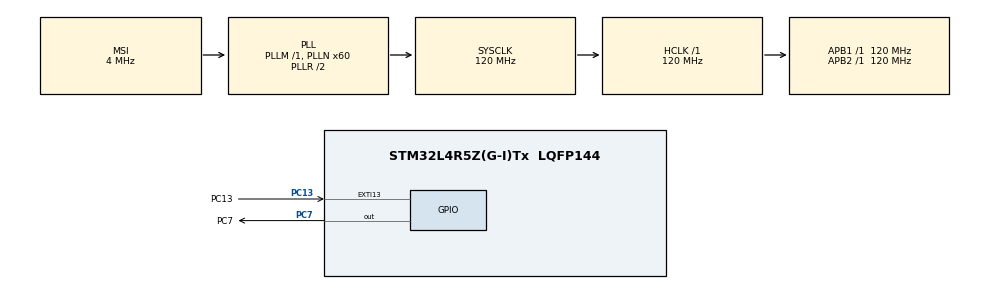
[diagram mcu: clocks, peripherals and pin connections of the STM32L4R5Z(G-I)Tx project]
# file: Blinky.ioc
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Mcu.Family=STM32L4
Mcu.Name=STM32L4R5Z(G-I)Tx
Mcu.Package=LQFP144
NVIC.EXTI15_10_IRQn=true\:1\:0\:true\:false\:true\:true\:true
NVIC.PriorityGroup=NVIC_PRIORITYGROUP_4
PA13\ (JTMS/SWDIO).Mode=Serial_Wire
PA13\ (JTMS/SWDIO).Signal=SYS_JTMS-SWDIO
PA14\ (JTCK/SWCLK).Mode=Serial_Wire
PA14\ (JTCK/SWCLK).Signal=SYS_JTCK-SWCLK
PC13.GPIO_Label=PC13
PC13.Signal=GPXTI13
PC7.GPIO_Label=PC7
PC7.GPIO_Speed=GPIO_SPEED_FREQ_HIGH
PC7.Signal=GPIO_Output
ProjectManager.HeapSize=0x200
ProjectManager.StackSize=0x400
ProjectManager.TargetToolchain=TrueSTUDIO
RCC.AHBFreq_Value=120000000
RCC.APB1Freq_Value=120000000
RCC.APB1TimFreq_Value=120000000
RCC.APB2Freq_Value=120000000
RCC.APB2TimFreq_Value=120000000
RCC.CortexFreq_Value=120000000
RCC.HCLKFreq_Value=120000000
RCC.HSE_VALUE=8000000
RCC.HSI48_VALUE=48000000
RCC.HSI_VALUE=16000000
RCC.LSE_VALUE=32768
RCC.MSI_VALUE=4000000
RCC.PLLN=60
RCC.SYSCLKFreq_VALUE=120000000
RCC.SYSCLKSource=RCC_SYSCLKSOURCE_PLLCLK
RCC.VCOOutputFreq_Value=240000000
board=custom

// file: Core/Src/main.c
/* USER CODE BEGIN Header */
/**
  ******************************************************************************
  * @file           : main.c
  * @brief          : Main program body
  ******************************************************************************
  * @attention
  *
  * Copyright (c) 2021 STMicroelectronics.
  * All rights reserved.
  *
  * This software is licensed under terms that can be found in the LICENSE file
  * in the root directory of this software component.
  * If no LICENSE file comes with this software, it is provided AS-IS.
  *
  ******************************************************************************
  */
/* USER CODE END Header */
#include "main.h"

void SystemClock_Config(void);
static void MX_GPIO_Init(void);

/* USER CODE BEGIN 0 */
uint8_t MODE_SELECTION;
/* USER CODE END 0 */

int main(void)
{

  /* MCU Configuration--------------------------------------------------------*/

  /* Reset of all peripherals, Initializes the Flash interface and the Systick. */
  HAL_Init();

  /* Configure the system clock */
  SystemClock_Config();

  /* Initialize all configured peripherals */
  MX_GPIO_Init();

  /* Infinite loop */
  while (1)
  {
// 	  if (MODE_SELECTION == 0) {

	  /* Toggle LEDs - Use the HAL functions from stm32l4xx_hal_gpio.c file */
	  HAL_GPIO_TogglePin(GPIOC, GPIO_PIN_7); //LD1 (green) – PC7
	  HAL_Delay(1000); //100ms // AMER: Updated this to 1000s to increase delay between each blink

//	Othman- function not needed, only blinking
// 	  } else if (MODE_SELECTION == 1) {
// 	  /* Turn OFF the LEDs - Use the HAL functions from stm32l4xx_hal_gpio.c file
// 	  */
// 	  HAL_GPIO_WritePin(GPIOC, GPIO_PIN_7, GPIO_PIN_RESET); //Turn off LD1 (green)
// 	  HAL_Delay(100); //100ms
// 	  } else if (MODE_SELECTION == 2) {
// 	  /* Turn ON the LED - Use the HAL functions from stm32l4xx_hal_gpio.c file */
// 	  HAL_GPIO_WritePin(GPIOC, GPIO_PIN_7, GPIO_PIN_SET);//LD1 (green) – PC7
// 	  HAL_Delay(1000);//1secs
// 	  }
  }
}

void SystemClock_Config(void)
{
  RCC_OscInitTypeDef RCC_OscInitStruct = {0};
  RCC_ClkInitTypeDef RCC_ClkInitStruct = {0};

  /** Configure the main internal regulator output voltage
  */
  if (HAL_PWREx_ControlVoltageScaling(PWR_REGULATOR_VOLTAGE_SCALE1_BOOST) != HAL_OK)
  {
    Error_Handler();
  }
  /** Initializes the RCC Oscillators according to the specified parameters
  * in the RCC_OscInitTypeDef structure.
  */
  RCC_OscInitStruct.OscillatorType = RCC_OSCILLATORTYPE_MSI;
  RCC_OscInitStruct.MSIState = RCC_MSI_ON;
  RCC_OscInitStruct.MSICalibrationValue = 0;
  RCC_OscInitStruct.MSIClockRange = RCC_MSIRANGE_6;
  RCC_OscInitStruct.PLL.PLLState = RCC_PLL_ON;
  RCC_OscInitStruct.PLL.PLLSource = RCC_PLLSOURCE_MSI;
  RCC_OscInitStruct.PLL.PLLM = 1;
  RCC_OscInitStruct.PLL.PLLN = 60;
  RCC_OscInitStruct.PLL.PLLP = RCC_PLLP_DIV2;
  RCC_OscInitStruct.PLL.PLLQ = RCC_PLLQ_DIV2;
  RCC_OscInitStruct.PLL.PLLR = RCC_PLLR_DIV2;
  if (HAL_RCC_OscConfig(&RCC_OscInitStruct) != HAL_OK)
  {
    Error_Handler();
  }
  /** Initializes the CPU, AHB and APB buses clocks
  */
  RCC_ClkInitStruct.ClockType = RCC_CLOCKTYPE_HCLK|RCC_CLOCKTYPE_SYSCLK
                              |RCC_CLOCKTYPE_PCLK1|RCC_CLOCKTYPE_PCLK2;
  RCC_ClkInitStruct.SYSCLKSource = RCC_SYSCLKSOURCE_PLLCLK;
  RCC_ClkInitStruct.AHBCLKDivider = RCC_SYSCLK_DIV1;
  RCC_ClkInitStruct.APB1CLKDivider = RCC_HCLK_DIV1;
  RCC_ClkInitStruct.APB2CLKDivider = RCC_HCLK_DIV1;

  if (HAL_RCC_ClockConfig(&RCC_ClkInitStruct, FLASH_LATENCY_5) != HAL_OK)
  {
    Error_Handler();
  }
}

static void MX_GPIO_Init(void)
{
  GPIO_InitTypeDef GPIO_InitStruct = {0};

  /* GPIO Ports Clock Enable */
  __HAL_RCC_GPIOC_CLK_ENABLE();
  __HAL_RCC_GPIOA_CLK_ENABLE();

  /*Configure GPIO pin Output Level */
  HAL_GPIO_WritePin(GPIOC, GPIO_PIN_7, GPIO_PIN_RESET);

  /*Configure GPIO pin : PC13 */
  GPIO_InitStruct.Pin = GPIO_PIN_13;
  GPIO_InitStruct.Mode = GPIO_MODE_IT_RISING;
  GPIO_InitStruct.Pull = GPIO_NOPULL;
  HAL_GPIO_Init(GPIOC, &GPIO_InitStruct);

  /*Configure GPIO pin : PC7 */
  GPIO_InitStruct.Pin = GPIO_PIN_7;
  GPIO_InitStruct.Mode = GPIO_MODE_OUTPUT_PP;
  GPIO_InitStruct.Pull = GPIO_NOPULL;
  GPIO_InitStruct.Speed = GPIO_SPEED_FREQ_HIGH;
  HAL_GPIO_Init(GPIOC, &GPIO_InitStruct);

  /* EXTI interrupt init*/
  HAL_NVIC_SetPriority(EXTI15_10_IRQn, 1, 0);
  HAL_NVIC_EnableIRQ(EXTI15_10_IRQn);

}

/* USER CODE BEGIN 4 */
/**
* @brief EXTI line detection callback. The function will be call by EXTI15_10_IRQHandler in “stm32l4xx_it.c” .
* @param GPIO_Pin: Specifies the pins connected EXTI line
* @retval None
*/
void HAL_GPIO_EXTI_Callback(uint16_t GPIO_Pin)
{
	if(GPIO_Pin == GPIO_PIN_13)
{
			MODE_SELECTION++;
			if(MODE_SELECTION > 2) MODE_SELECTION=0;
			/* Debounce - wait until the button is released . Read the GPIO to get the state. Refer to the schematics. */
			/* - Use the HAL functions from stm32l4xx_hal_gpio.c file */
			while(HAL_GPIO_ReadPin(GPIOC, GPIO_PIN_13) != GPIO_PIN_RESET);//Blue pushbutton – PC13
}
}
/* USER CODE END 4 */

void Error_Handler(void)
{
  __disable_irq();
  while (1)
  {
  }
}
